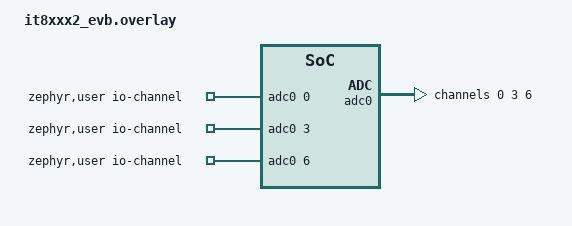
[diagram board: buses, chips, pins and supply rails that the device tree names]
/ {
	zephyr,user {
		io-channels = <&adc0 0>, <&adc0 3>, <&adc0 6>;
	};
	aliases {
		adc0 = &adc0;
	};
};

&adc0 {
	#address-cells = <1>;
	#size-cells = <0>;

	pinctrl-0 = <&adc0_ch0_gpi0_default &adc0_ch3_gpi3_default &adc0_ch6_gpi6_default>;

	pinctrl-names = "default";

	channel@0 {
		reg = <0>;
		zephyr,gain = "ADC_GAIN_1";
		zephyr,reference = "ADC_REF_INTERNAL";
		zephyr,acquisition-time = <ADC_ACQ_TIME_DEFAULT>;
		zephyr,resolution = <10>;
	};
	channel@3 {
		reg = <3>;
		zephyr,gain = "ADC_GAIN_1";
		zephyr,reference = "ADC_REF_INTERNAL";
		zephyr,acquisition-time = <ADC_ACQ_TIME_DEFAULT>;
		zephyr,resolution = <10>;
	};
	channel@6 {
		reg = <6>;
		zephyr,gain = "ADC_GAIN_1";
		zephyr,reference = "ADC_REF_INTERNAL";
		zephyr,acquisition-time = <ADC_ACQ_TIME_DEFAULT>;
		zephyr,resolution = <10>;
	};
};
